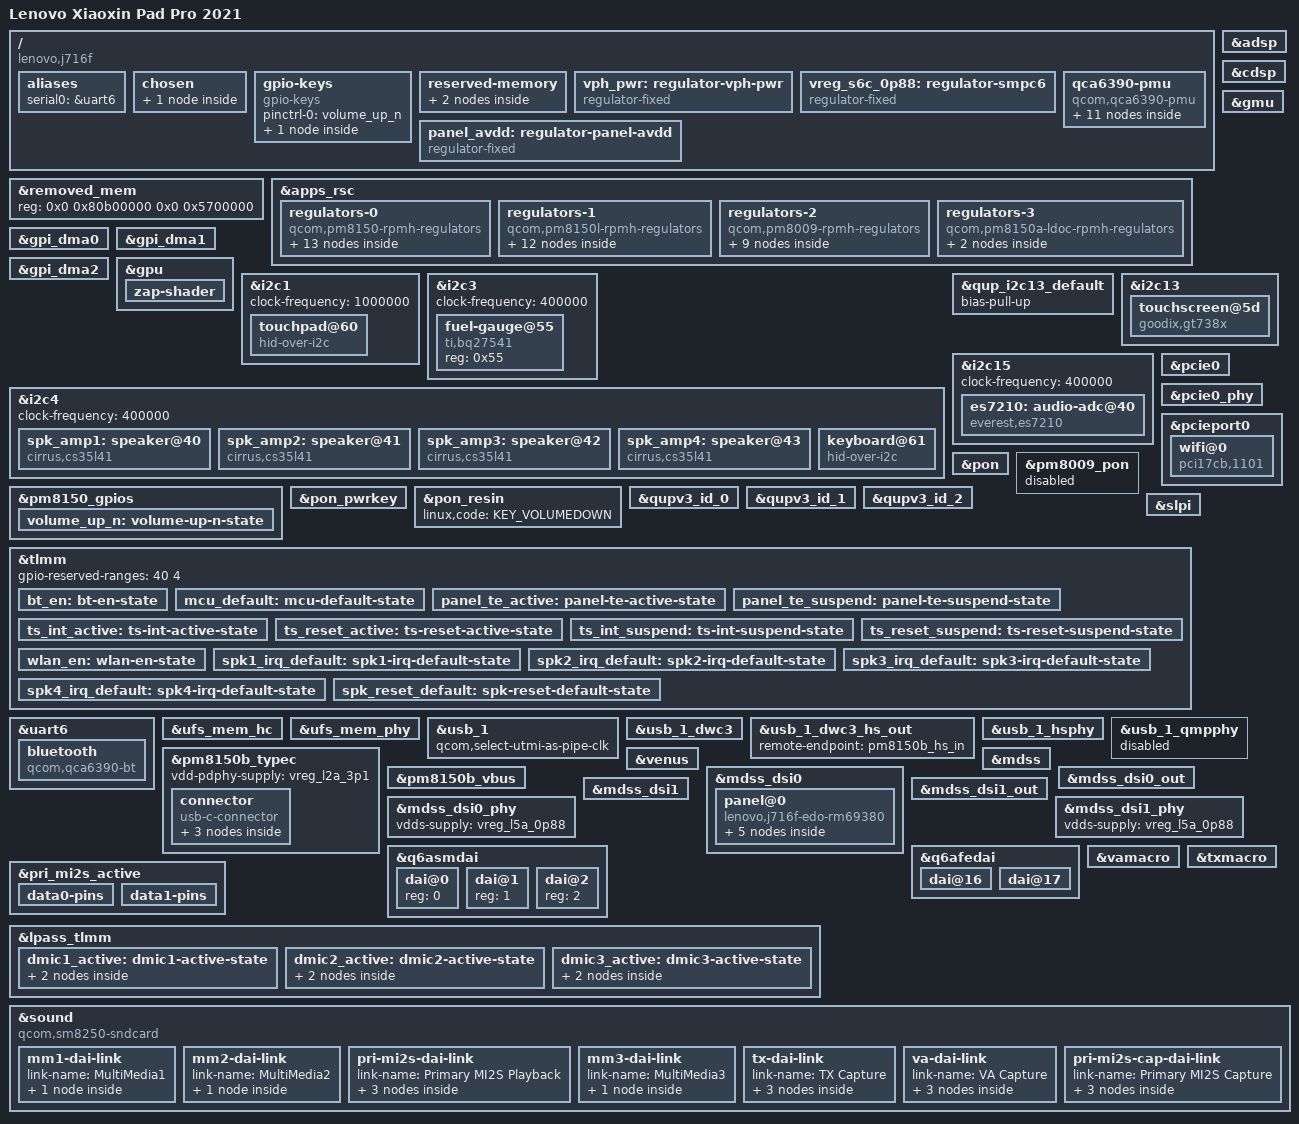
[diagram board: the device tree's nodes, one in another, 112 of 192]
// SPDX-License-Identifier: GPL-2.0-only
/*
 * Copyright (c) 2025, David Wronek <david@mainlining.org>
 */

/dts-v1/;

#include <dt-bindings/arm/qcom,ids.h>
#include <dt-bindings/gpio/gpio.h>
#include <dt-bindings/regulator/qcom,rpmh-regulator.h>
#include <dt-bindings/sound/qcom,q6afe.h>
#include <dt-bindings/usb/pd.h>
#include <dt-bindings/sound/qcom,q6asm.h>
#include "sm8250.dtsi"
#include "pm8009.dtsi"
#include "pm8150.dtsi"
#include "pm8150b.dtsi"
#include "pm8150l.dtsi"

/ {
	model = "Lenovo Xiaoxin Pad Pro 2021";
	compatible = "lenovo,j716f", "qcom,sm8250";
	chassis-type = "tablet";

	/* required for bootloader to select correct board */
	qcom,msm-id = <QCOM_ID_SM8250 0x20001>; /* SM8250 v2.1 */
	qcom,board-id = <0x2010008 0>;

	aliases {
		serial0 = &uart6;
	};

	chosen {
		#address-cells = <2>;
		#size-cells = <2>;
		ranges;

		framebuffer: framebuffer@9c000000 {
			compatible = "simple-framebuffer";
			reg = <0x0 0x9c000000 0x0 0x1f00000>;
			width = <2560>;
			height = <1600>;
			stride = <(2560 * 4)>;
			format = "a8r8g8b8";
		};
	};

	gpio-keys {
		compatible = "gpio-keys";

		pinctrl-names = "default";
		pinctrl-0 = <&volume_up_n>;

		key-vol-up {
			label = "Volume Up";
			linux,code = <KEY_VOLUMEUP>;
			gpios = <&pm8150_gpios 6 GPIO_ACTIVE_LOW>;
			debounce-interval = <15>;
			linux,can-disable;
			wakeup-source;
		};
	};

	reserved-memory {
		/*
		 * The bootloader loads the splash into the start of this
		 * region; the panel itself needs 2560x1600x4 = 16 MiB, so
		 * 31 MiB is plenty.  The size matters: everything after this
		 * reservation belongs to the general allocator, so it also
		 * bounds the simple-framebuffer below (see chosen).
		 */
		cont_splash_mem: memory@9c000000 {
			reg = <0x0 0x9c000000 0x0 0x1f00000>;
			no-map;
		};

		/*
		 * Phase M2: crash log that survives a reboot.  A watchdog or
		 * panic reset keeps the DDR contents for the next boot, which
		 * is exactly the case we need for the CPU-idle freeze seen on
		 * 2026-11-07 (no pstore at all back then).
		 *
		 * Phase M6: this used to sit at 0x9e100000, the last 2 MiB of
		 * the then 35 MiB simple-framebuffer range.  Both the fbdev
		 * console and pstore wrote the same pages, so every reset left
		 * /sys/fs/pstore empty (M3 and M5 both saw 0 entries).  Keep
		 * it strictly above both the splash reservation and the
		 * framebuffer: 0x9c000000 + 31 MiB = 0x9df00000, and the
		 * ramoops zone starts at 0x9f000000, well clear of it.
		 */
		ramoops@9f000000 {
			compatible = "ramoops";
			reg = <0x0 0x9f000000 0x0 0x200000>;
			record-size = <0x40000>;
			console-size = <0x80000>;
			pmsg-size = <0x40000>;
		};
	};

	vph_pwr: regulator-vph-pwr {
		compatible = "regulator-fixed";

		regulator-name = "vph_pwr";
		regulator-min-microvolt = <3700000>;
		regulator-max-microvolt = <3700000>;
		regulator-always-on;
		regulator-boot-on;
	};

	/* S6c is really ebi.lvl but it's there for supply map completeness sake. */
	vreg_s6c_0p88: regulator-smpc6 {
		compatible = "regulator-fixed";

		regulator-name = "vreg_s6c_0p88";
		regulator-min-microvolt = <880000>;
		regulator-max-microvolt = <880000>;
		regulator-always-on;

		vin-supply = <&vph_pwr>;
	};

	/*
	 * EDO EB50QBC73.A panel AVDD rail.  The 5.5 V value is the nominal
	 * rail generated by the board's boost; the GPIO is the real control.
	 */
	panel_avdd: regulator-panel-avdd {
		compatible = "regulator-fixed";

		regulator-name = "display_panel_avdd";
		regulator-min-microvolt = <5500000>;
		regulator-max-microvolt = <5500000>;
		regulator-enable-ramp-delay = <233>;
		regulator-boot-on;

		enable-gpios = <&tlmm 61 GPIO_ACTIVE_HIGH>;
		vin-supply = <&vph_pwr>;
	};

	qca6390-pmu {
		compatible = "qcom,qca6390-pmu";

		pinctrl-names = "default";
		pinctrl-0 = <&bt_en>, <&wlan_en>;

		vddaon-supply = <&vreg_s6a_0p6>;
		vddpmu-supply = <&vreg_s2f_0p5>;
		vddrfa0p95-supply = <&vreg_s6a_0p6>;
		vddrfa1p3-supply = <&vreg_s8c_1p2>;
		vddrfa1p9-supply = <&vreg_s5a_1p9>;
		vddpcie1p3-supply = <&vreg_s8c_1p2>;
		vddpcie1p9-supply = <&vreg_s5a_1p9>;
		vddio-supply = <&vreg_s4a_1p8>;

		wlan-enable-gpios = <&tlmm 20 GPIO_ACTIVE_HIGH>;
		bt-enable-gpios = <&tlmm 21 GPIO_ACTIVE_HIGH>;

		regulators {
			vreg_pmu_rfa_cmn: ldo0 {
				regulator-name = "vreg_pmu_rfa_cmn";
			};

			vreg_pmu_aon_0p59: ldo1 {
				regulator-name = "vreg_pmu_aon_0p59";
			};

			vreg_pmu_wlcx_0p8: ldo2 {
				regulator-name = "vreg_pmu_wlcx_0p8";
			};

			vreg_pmu_wlmx_0p85: ldo3 {
				regulator-name = "vreg_pmu_wlmx_0p85";
			};

			vreg_pmu_btcmx_0p85: ldo4 {
				regulator-name = "vreg_pmu_btcmx_0p85";
			};

			vreg_pmu_rfa_0p8: ldo5 {
				regulator-name = "vreg_pmu_rfa_0p8";
			};

			vreg_pmu_rfa_1p2: ldo6 {
				regulator-name = "vreg_pmu_rfa_1p2";
			};

			vreg_pmu_rfa_1p7: ldo7 {
				regulator-name = "vreg_pmu_rfa_1p7";
			};

			vreg_pmu_pcie_0p9: ldo8 {
				regulator-name = "vreg_pmu_pcie_0p9";
			};

			vreg_pmu_pcie_1p8: ldo9 {
				regulator-name = "vreg_pmu_pcie_1p8";
			};
		};
	};
};

/*
 * Candidate K1 of the v60 platform audit: the vendor tree keeps
 * 0x80b00000 + 0x5700000 (87 MiB) out of the allocator and ends that
 * range exactly where the TrustZone carveout ends -- 0x86200000, i.e.
 * qseecom@82400000 + 0x3e00000 ("TZApps Reserved" in the XBL EFI
 * memory map, "secapp-region" in the vendor DT).  The imported upstream
 * value stops 4 MiB short and leaves [0x85e00000, 0x86200000)
 * allocatable by Linux.  Restore the vendor extent; this is the only
 * variable the validation round changes.
 *
 * See docs/project/V60-PLATFORM-AUDIT.md, candidate K1.
 */
&removed_mem {
	reg = <0x0 0x80b00000 0x0 0x5700000>;
};

&adsp {
	firmware-name = "qcom/sm8250/LENOVO/J716F/adsp.mbn";
	status = "okay";
};

&apps_rsc {
	regulators-0 {
		compatible = "qcom,pm8150-rpmh-regulators";
		qcom,pmic-id = "a";

		vdd-s1-supply = <&vph_pwr>;
		vdd-s2-supply = <&vph_pwr>;
		vdd-s3-supply = <&vph_pwr>;
		vdd-s4-supply = <&vph_pwr>;
		vdd-s5-supply = <&vph_pwr>;
		vdd-s6-supply = <&vph_pwr>;
		vdd-s7-supply = <&vph_pwr>;
		vdd-s8-supply = <&vph_pwr>;
		vdd-s9-supply = <&vph_pwr>;
		vdd-s10-supply = <&vph_pwr>;
		vdd-l1-l8-l11-supply = <&vreg_s6c_0p88>;
		vdd-l2-l10-supply = <&vreg_bob>;
		vdd-l3-l4-l5-l18-supply = <&vreg_s6a_0p6>;
		vdd-l6-l9-supply = <&vreg_s8c_1p2>;
		vdd-l7-l12-l14-l15-supply = <&vreg_s5a_1p9>;
		vdd-l13-l16-l17-supply = <&vreg_bob>;

		/* (S1+S2+S3) - cx.lvl (ARC) */

		vreg_s4a_1p8: smps4 {
			regulator-name = "vreg_s4a_1p8";
			regulator-min-microvolt = <1800000>;
			regulator-max-microvolt = <1920000>;
			regulator-initial-mode = <RPMH_REGULATOR_MODE_HPM>;
			regulator-allow-set-load;
			regulator-allowed-modes = <RPMH_REGULATOR_MODE_LPM
						   RPMH_REGULATOR_MODE_HPM>;
		};

		vreg_s5a_1p9: smps5 {
			regulator-name = "vreg_s5a_1p9";
			regulator-min-microvolt = <1900000>;
			regulator-max-microvolt = <2040000>;
			regulator-initial-mode = <RPMH_REGULATOR_MODE_HPM>;
		};

		vreg_s6a_0p6: smps6 {
			regulator-name = "vreg_s6a_0p6";
			regulator-min-microvolt = <600000>;
			regulator-max-microvolt = <1128000>;
			regulator-initial-mode = <RPMH_REGULATOR_MODE_HPM>;
		};

		vreg_l2a_3p1: ldo2 {
			regulator-name = "vreg_l2a_3p1";
			regulator-min-microvolt = <3072000>;
			regulator-max-microvolt = <3072000>;
			regulator-initial-mode = <RPMH_REGULATOR_MODE_HPM>;
		};

		/* L3 is unused, L4 - lmx.lvl (ARC) */

		vreg_l5a_0p88: ldo5 {
			regulator-name = "vreg_l5a_0p88";
			regulator-min-microvolt = <880000>;
			regulator-max-microvolt = <880000>;
			regulator-initial-mode = <RPMH_REGULATOR_MODE_HPM>;
		};

		vreg_l6a_1p2: ldo6 {
			regulator-name = "vreg_l6a_1p2";
			regulator-min-microvolt = <1200000>;
			regulator-max-microvolt = <1200000>;
			regulator-initial-mode = <RPMH_REGULATOR_MODE_HPM>;
			regulator-allow-set-load;
			regulator-allowed-modes = <RPMH_REGULATOR_MODE_LPM
						   RPMH_REGULATOR_MODE_HPM>;
		};

		/* L7 is unused. */

		vreg_l9a_1p2: ldo9 {
			regulator-name = "vreg_l9a_1p2";
			regulator-min-microvolt = <1200000>;
			regulator-max-microvolt = <1200000>;
			regulator-initial-mode = <RPMH_REGULATOR_MODE_HPM>;
		};

		/* L10 is unused, L11 - lcx.lvl (ARC) */

		vreg_l12a_1p8: ldo12 {
			regulator-name = "vreg_l12a_1p8";
			regulator-min-microvolt = <1800000>;
			regulator-max-microvolt = <1800000>;
			regulator-initial-mode = <RPMH_REGULATOR_MODE_HPM>;
		};

		vreg_l13a_3p0: ldo13 {
			regulator-name = "vreg_l13a_3p0";
			regulator-min-microvolt = <3008000>;
			regulator-max-microvolt = <3008000>;
			regulator-initial-mode = <RPMH_REGULATOR_MODE_HPM>;
		};

		vreg_l14a_1p88: ldo14 {
			regulator-name = "vreg_l14a_1p88";
			regulator-min-microvolt = <1800000>;
			regulator-max-microvolt = <1880000>;
			regulator-initial-mode = <RPMH_REGULATOR_MODE_HPM>;
		};

		/* L15 is unused. */

		vreg_l16a_3p3: ldo16 {
			regulator-name = "vreg_l16a_3p3";
			regulator-min-microvolt = <3024000>;
			regulator-max-microvolt = <3304000>;
			regulator-initial-mode = <RPMH_REGULATOR_MODE_HPM>;
		};

		vreg_l17a_2p5: ldo17 {
			regulator-name = "vreg_l17a_2p5";
			regulator-min-microvolt = <2496000>;
			regulator-max-microvolt = <3008000>;
			regulator-initial-mode = <RPMH_REGULATOR_MODE_HPM>;
			regulator-allow-set-load;
			regulator-allowed-modes = <RPMH_REGULATOR_MODE_LPM
						   RPMH_REGULATOR_MODE_HPM>;
		};

		vreg_l18a_0p9: ldo18 {
			regulator-name = "vreg_l18a_0p9";
			regulator-min-microvolt = <800000>;
			regulator-max-microvolt = <920000>;
			regulator-initial-mode = <RPMH_REGULATOR_MODE_HPM>;
		};
	};

	/*
	 * Remaining regulators that are not yet supported:
	 * OLEDB: 4925000-8100000
	 * ab: 4600000-6100000
	 * ibb: 800000-5400000
	 */

	regulators-1 {
		compatible = "qcom,pm8150l-rpmh-regulators";
		qcom,pmic-id = "c";

		vdd-s1-supply = <&vph_pwr>;
		vdd-s2-supply = <&vph_pwr>;
		vdd-s3-supply = <&vph_pwr>;
		vdd-s4-supply = <&vph_pwr>;
		vdd-s5-supply = <&vph_pwr>;
		vdd-s6-supply = <&vph_pwr>;
		vdd-s7-supply = <&vph_pwr>;
		vdd-s8-supply = <&vph_pwr>;
		vdd-l1-l8-supply = <&vreg_s4a_1p8>;
		vdd-l2-l3-supply = <&vreg_s8c_1p2>;
		vdd-l4-l5-l6-supply = <&vreg_bob>;
		vdd-l7-l11-supply = <&vreg_bob>;
		vdd-l9-l10-supply = <&vreg_bob>;
		vdd-bob-supply = <&vph_pwr>;

		vreg_bob: bob {
			regulator-name = "vreg_bob";
			regulator-min-microvolt = <3008000>;
			regulator-max-microvolt = <3960000>;
			regulator-initial-mode = <RPMH_REGULATOR_MODE_AUTO>;
		};

		/*
		 * S1-S6 are ARCs:
		 * (S1+S2) - gfx.lvl,
		 * S3 - mx.lvl,
		 * (S4+S5) - mmcx.lvl,
		 * S6 - ebi.lvl
		 */

		vreg_s7c_0p35: smps7 {
			regulator-name = "vreg_s7c_0p35";
			regulator-min-microvolt = <348000>;
			regulator-max-microvolt = <1000000>;
			regulator-initial-mode = <RPMH_REGULATOR_MODE_HPM>;
		};

		vreg_s8c_1p2: smps8 {
			regulator-name = "vreg_s8c_1p2";
			regulator-min-microvolt = <1200000>;
			regulator-max-microvolt = <1400000>;
			regulator-initial-mode = <RPMH_REGULATOR_MODE_HPM>;
		};

		vreg_l1c_1p8: ldo1 {
			regulator-name = "vreg_l1c_1p8";
			regulator-min-microvolt = <1800000>;
			regulator-max-microvolt = <1800000>;
			regulator-initial-mode = <RPMH_REGULATOR_MODE_HPM>;
		};

		/* L2 is unused. */

		vreg_l3c_0p8: ldo3 {
			regulator-name = "vreg_l3c_0p8";
			regulator-min-microvolt = <800000>;
			regulator-max-microvolt = <1200000>;
			regulator-initial-mode = <RPMH_REGULATOR_MODE_HPM>;
		};

		/* L4 is unused. */

		vreg_l5c_1p8: ldo5 {
			regulator-name = "vreg_l5c_1p8";
			regulator-min-microvolt = <1800000>;
			regulator-max-microvolt = <2800000>;
			regulator-initial-mode = <RPMH_REGULATOR_MODE_HPM>;
		};

		vreg_l6c_2p9: ldo6 {
			regulator-name = "vreg_l6c_2p9";
			regulator-min-microvolt = <1800000>;
			regulator-max-microvolt = <2960000>;
			regulator-initial-mode = <RPMH_REGULATOR_MODE_HPM>;
			regulator-allow-set-load;
			regulator-allowed-modes = <RPMH_REGULATOR_MODE_LPM
						   RPMH_REGULATOR_MODE_HPM>;
		};

		vreg_l7c_2p85: ldo7 {
			regulator-name = "vreg_l7c_2p85";
			regulator-min-microvolt = <2856000>;
			regulator-max-microvolt = <3104000>;
			regulator-initial-mode = <RPMH_REGULATOR_MODE_HPM>;
		};

		vreg_l8c_1p8: ldo8 {
			regulator-name = "vreg_l8c_1p8";
			regulator-min-microvolt = <1800000>;
			regulator-max-microvolt = <1800000>;
			regulator-initial-mode = <RPMH_REGULATOR_MODE_HPM>;
		};

		vreg_l9c_2p9: ldo9 {
			regulator-name = "vreg_l9c_2p9";
			regulator-min-microvolt = <2704000>;
			regulator-max-microvolt = <2960000>;
			regulator-initial-mode = <RPMH_REGULATOR_MODE_HPM>;
			regulator-allow-set-load;
			regulator-allowed-modes = <RPMH_REGULATOR_MODE_LPM
						   RPMH_REGULATOR_MODE_HPM>;
		};

		vreg_l10c_3p3: ldo10 {
			regulator-name = "vreg_l10c_3p3";
			regulator-min-microvolt = <3000000>;
			regulator-max-microvolt = <3312000>;
			regulator-initial-mode = <RPMH_REGULATOR_MODE_HPM>;
		};

		vreg_l11c_3p3: ldo11 {
			regulator-name = "vreg_l11c_3p0";
			regulator-min-microvolt = <3104000>;
			regulator-max-microvolt = <3304000>;
			regulator-initial-mode = <RPMH_REGULATOR_MODE_HPM>;
		};
	};

	regulators-2 {
		compatible = "qcom,pm8009-rpmh-regulators";
		qcom,pmic-id = "f";

		vdd-s1-supply = <&vph_pwr>;
		vdd-s2-supply = <&vreg_bob>;
		vdd-l2-supply = <&vreg_s8c_1p2>;
		vdd-l5-l6-supply = <&vreg_bob>;
		vdd-l7-supply = <&vreg_s4a_1p8>;

		vreg_s1f_1p2: smps1 {
			regulator-name = "vreg_s1f_1p2";
			regulator-min-microvolt = <1200000>;
			regulator-max-microvolt = <1200000>;
			regulator-initial-mode = <RPMH_REGULATOR_MODE_HPM>;
		};

		vreg_s2f_0p5: smps2 {
			regulator-name = "vreg_s2f_0p5";
			regulator-min-microvolt = <512000>;
			regulator-max-microvolt = <1100000>;
			regulator-initial-mode = <RPMH_REGULATOR_MODE_HPM>;
		};

		vreg_l1f_1p2: ldo1 {
			regulator-name = "vreg_l1f_1p2";
			regulator-min-microvolt = <1104000>;
			regulator-max-microvolt = <1200000>;
			regulator-initial-mode = <RPMH_REGULATOR_MODE_HPM>;
		};

		vreg_l2f_1p2: ldo2 {
			regulator-name = "vreg_l2f_1p1";
			regulator-min-microvolt = <1200000>;
			regulator-max-microvolt = <1200000>;
			regulator-initial-mode = <RPMH_REGULATOR_MODE_HPM>;
		};

		vreg_l3f_1p2: ldo3 {
			regulator-name = "vreg_l3f_1p2";
			regulator-min-microvolt = <1056000>;
			regulator-max-microvolt = <1200000>;
			regulator-initial-mode = <RPMH_REGULATOR_MODE_HPM>;
		};

		vreg_l4f_1p3: ldo4 {
			regulator-name = "vreg_l4f_1p3";
			regulator-min-microvolt = <1096000>;
			regulator-max-microvolt = <1304000>;
			regulator-initial-mode = <RPMH_REGULATOR_MODE_HPM>;
		};

		vreg_l5f_2p8: ldo5 {
			regulator-name = "vreg_l5f_2p85";
			regulator-min-microvolt = <2800000>;
			regulator-max-microvolt = <3000000>;
			regulator-initial-mode = <RPMH_REGULATOR_MODE_HPM>;
		};

		vreg_l6f_2p8: ldo6 {
			regulator-name = "vreg_l6f_2p8";
			regulator-min-microvolt = <2800000>;
			regulator-max-microvolt = <3000000>;
			regulator-initial-mode = <RPMH_REGULATOR_MODE_HPM>;
		};

		vreg_l7f_1p8: ldo7 {
			regulator-name = "vreg_l7f_1p8";
			regulator-min-microvolt = <1800000>;
			regulator-max-microvolt = <1800000>;
			regulator-initial-mode = <RPMH_REGULATOR_MODE_HPM>;
		};
	};

	/*
	 * PM8150A LDOs.  The touch controller's 1.8 V core rail is ldoc1
	 * (vendor: pm8150a_l1 -> goodix-gt738x@5d vdd-supply); ldoc10 is
	 * used by the fingerprint sensor.
	 */
	regulators-3 {
		compatible = "qcom,pm8150a-ldoc-rpmh-regulators";
		qcom,pmic-id = "d";

		vdd-l1-l2-supply = <&vph_pwr>;
		vdd-l3-supply = <&vph_pwr>;
		vdd-l4-l5-l6-supply = <&vph_pwr>;
		vdd-l7-supply = <&vph_pwr>;
		vdd-l8-supply = <&vph_pwr>;
		vdd-l9-l10-supply = <&vph_pwr>;
		vdd-l11-supply = <&vph_pwr>;
		vdd-l12-supply = <&vph_pwr>;

		vreg_l1d_1p8: ldoc1 {
			regulator-name = "vreg_l1d_1p8";
			regulator-min-microvolt = <1800000>;
			regulator-max-microvolt = <1800000>;
		};

		vreg_l10d_3p0: ldoc10 {
			regulator-name = "vreg_l10d_3p0";
			regulator-min-microvolt = <3000000>;
			regulator-max-microvolt = <3312000>;
			regulator-initial-mode = <RPMH_REGULATOR_MODE_HPM>;
		};
	};
};

&cdsp {
	firmware-name = "qcom/sm8250/LENOVO/J716F/cdsp.mbn";
	status = "okay";
};

&gmu {
	status = "okay";
};

&gpi_dma0 {
	status = "okay";
};

&gpi_dma1 {
	status = "okay";
};

&gpi_dma2 {
	status = "okay";
};

&gpu {
	status = "okay";

	zap-shader {
		memory-region = <&gpu_mem>;
		firmware-name = "qcom/sm8250/LENOVO/J716F/a650_zap.mbn";
	};
};

&i2c1 {
	clock-frequency = <1000000>;
	status = "okay";

	touchpad@60 {
		compatible = "hid-over-i2c";
		reg = <0x60>;

		vdd-supply = <&vreg_l16a_3p3>;
		vddl-supply = <&vreg_l8c_1p8>;

		interrupt-parent = <&tlmm>;
		interrupts = <14 IRQ_TYPE_LEVEL_LOW>;

		hid-descr-addr = <0x01>;
		post-power-on-delay-ms = <100>;
	};
};

&i2c3 {
	clock-frequency = <400000>;
	status = "okay";

	fuel-gauge@55 {
		compatible = "ti,bq27541";
		reg = <0x55>;
	};
};

&i2c4 {
	clock-frequency = <400000>;
	status = "okay";

	/* onsemi NB7VPQ904M USB redriver @ 19 */

	/*
	 * Four CS35L41 speaker amplifiers.  All share reset gpio 131 and
	 * the primary MI2S bit clock; IRQs are 67, 113, 126 and 68.
	 * VA is the 3.3 V logic rail, VP is the battery rail feeding the
	 * internal boost converter.
	 */
	spk_amp1: speaker@40 {
		compatible = "cirrus,cs35l41";
		reg = <0x40>;
		#sound-dai-cells = <1>;

		interrupt-parent = <&tlmm>;
		interrupts = <67 IRQ_TYPE_LEVEL_LOW>;
		interrupt-controller;
		#interrupt-cells = <2>;
		interrupt-names = "cs35l41_1_irq";

		pinctrl-names = "default";
		pinctrl-0 = <&spk1_irq_default &spk_reset_default>;

		reset-gpios = <&tlmm 131 GPIO_ACTIVE_HIGH>;

		VA-supply = <&vreg_l16a_3p3>;
		VP-supply = <&vph_pwr>;

		cirrus,boost-type = <0>;
		cirrus,boost-peak-milliamp = <3500>;
		cirrus,boost-ind-nanohenry = <1000>;
		cirrus,boost-cap-microfarad = <15>;
		/* Without a boost target the amplifier stays silent. */
		cirrus,boost-ctl-millivolt = <4600>;
		cirrus,asp-sdout-hiz = <3>;
		cirrus,gpio2-src-select = <4>;
		cirrus,gpio2-output-enable;
	};

	spk_amp2: speaker@41 {
		compatible = "cirrus,cs35l41";
		reg = <0x41>;
		#sound-dai-cells = <1>;
		sound-name-prefix = "SPK2";

		interrupt-parent = <&tlmm>;
		interrupts = <113 IRQ_TYPE_LEVEL_LOW>;
		interrupt-controller;
		#interrupt-cells = <2>;
		interrupt-names = "cs35l41_2_irq";

		pinctrl-names = "default";
		pinctrl-0 = <&spk2_irq_default>;

		reset-gpios = <&tlmm 131 GPIO_ACTIVE_HIGH>;

		VA-supply = <&vreg_l16a_3p3>;
		VP-supply = <&vph_pwr>;

		cirrus,boost-type = <0>;
		cirrus,boost-peak-milliamp = <3500>;
		cirrus,boost-ind-nanohenry = <1000>;
		cirrus,boost-cap-microfarad = <15>;
		cirrus,boost-ctl-millivolt = <4600>;
		cirrus,asp-sdout-hiz = <3>;
		cirrus,gpio2-src-select = <4>;
		cirrus,gpio2-output-enable;
	};

	spk_amp3: speaker@42 {
		compatible = "cirrus,cs35l41";
		reg = <0x42>;
		#sound-dai-cells = <1>;
		sound-name-prefix = "SPK3";

		interrupt-parent = <&tlmm>;
		interrupts = <126 IRQ_TYPE_LEVEL_LOW>;
		interrupt-controller;
		#interrupt-cells = <2>;
		interrupt-names = "cs35l41_3_irq";

		pinctrl-names = "default";
		pinctrl-0 = <&spk3_irq_default>;

		reset-gpios = <&tlmm 131 GPIO_ACTIVE_HIGH>;

		VA-supply = <&vreg_l16a_3p3>;
		VP-supply = <&vph_pwr>;

		cirrus,boost-type = <0>;
		cirrus,boost-peak-milliamp = <3500>;
		cirrus,boost-ind-nanohenry = <1000>;
		cirrus,boost-cap-microfarad = <15>;
		cirrus,boost-ctl-millivolt = <4600>;
		cirrus,asp-sdout-hiz = <3>;
		cirrus,gpio2-src-select = <4>;
		cirrus,gpio2-output-enable;
	};

	spk_amp4: speaker@43 {
		compatible = "cirrus,cs35l41";
		reg = <0x43>;
		#sound-dai-cells = <1>;
		sound-name-prefix = "SPK4";

		interrupt-parent = <&tlmm>;
		interrupts = <68 IRQ_TYPE_LEVEL_LOW>;
		interrupt-controller;
		#interrupt-cells = <2>;
		interrupt-names = "cs35l41_4_irq";

		pinctrl-names = "default";
		pinctrl-0 = <&spk4_irq_default>;

		reset-gpios = <&tlmm 131 GPIO_ACTIVE_HIGH>;

		VA-supply = <&vreg_l16a_3p3>;
		VP-supply = <&vph_pwr>;

		cirrus,boost-type = <0>;
		cirrus,boost-peak-milliamp = <3500>;
		cirrus,boost-ind-nanohenry = <1000>;
		cirrus,boost-cap-microfarad = <15>;
		cirrus,boost-ctl-millivolt = <4600>;
		cirrus,asp-sdout-hiz = <3>;
		cirrus,gpio2-src-select = <4>;
		cirrus,gpio2-output-enable;
	};

	keyboard@61 {
		compatible = "hid-over-i2c";
		reg = <0x61>;

		vdd-supply = <&vreg_l16a_3p3>;
		vddl-supply = <&vreg_l8c_1p8>;

		pinctrl-names = "default";
		pinctrl-0 = <&mcu_default>;

		interrupt-parent = <&tlmm>;
		interrupts = <11 IRQ_TYPE_LEVEL_LOW>;

		hid-descr-addr = <0x1>;
		post-power-on-delay-ms = <100>;
	};
};

/*
 * The GT7385P touch controller is a GT9xx-protocol part (16-bit register
 * addresses), not a Berlin part.  The vendor uses 100 kHz on this long,
 * thin FPC and the GENI controller takes the GPI-DMA path otherwise; force
 * the FIFO/PIO path for this bus.
 */
&qup_i2c13_default {
	bias-pull-up;
};

&i2c13 {
	clock-frequency = <100000>;
	status = "okay";
	qcom,force-fifo;

	touchscreen@5d {
		compatible = "goodix,gt738x";
		reg = <0x5d>;
		goodix,debug-reports;

		interrupt-parent = <&tlmm>;
		interrupts = <39 IRQ_TYPE_EDGE_FALLING>;

		/*
		 * Both GPIOs are ACTIVE_HIGH: goodix_reset_no_int_sync()
		 * drives INT as an output to select the 0x5d I2C address
		 * before releasing reset.  An ACTIVE_LOW irq-gpios would
		 * select 0x14 instead and every read at 0x5d would time out.
		 */
		irq-gpios = <&tlmm 39 GPIO_ACTIVE_HIGH>;
		reset-gpios = <&tlmm 38 GPIO_ACTIVE_HIGH>;

		/*
		 * goodix.c prefixes this with "goodix/", so the blob is at
		 * /lib/firmware/goodix/j716f_cfg.bin.  Without the panel
		 * configuration the controller never enters normal reporting
		 * mode.
		 */
		goodix,config-name = "j716f_cfg.bin";

		/*
		 * Vendor rail map:
		 *   pm8150a_l1  (1.8 V) -> vdd-supply / avdd-supply
		 *   pm8150_l13  (3.0 V) -> AVDD28-supply
		 *   pm8150_l14  (1.8 V) -> VDDIO-supply / vddio-supply
		 */
		avdd-supply = <&vreg_l1d_1p8>;
		vdd-supply = <&vreg_l1d_1p8>;
		vddio-supply = <&vreg_l14a_1p88>;
		AVDD28-supply = <&vreg_l13a_3p0>;
		VDDIO-supply = <&vreg_l14a_1p88>;

		pinctrl-names = "default", "sleep";
		pinctrl-0 = <&ts_int_active &ts_reset_active>;
		pinctrl-1 = <&ts_int_suspend &ts_reset_suspend>;

		/* Coordinates already match display orientation. */
		touchscreen-size-x = <2560>;
		touchscreen-size-y = <1600>;
	};
};

&i2c15 {
	clock-frequency = <400000>;
	status = "okay";

	/* SMB1390 charger @ 10 */
	/* FSA4480 USB audio switch @ 43 */
	/* RTC6226 FM receiver @ 64 */
	/* HL6111R wireless charging IC @ 25 */

	/*
	 * Four-microphone ADC.  Its serial output feeds the primary MI2S
	 * capture direction, so data0/data1 must stay inputs on the SoC.
	 */
	es7210: audio-adc@40 {
		compatible = "everest,es7210";
		reg = <0x40>;

		vd-supply = <&vreg_l16a_3p3>;
		vp-supply = <&vreg_l8c_1p8>;

		#sound-dai-cells = <0>;
	};
};

&pcie0 {
	status = "okay";
};

&pcie0_phy {
	vdda-phy-supply = <&vreg_l5a_0p88>;
	vdda-pll-supply = <&vreg_l9a_1p2>;
	status = "okay";
};

&pcieport0 {
	wifi@0 {
		compatible = "pci17cb,1101";
		reg = <0x10000 0x0 0x0 0x0 0x0>;

		vddrfacmn-supply = <&vreg_pmu_rfa_cmn>;
		vddaon-supply = <&vreg_pmu_aon_0p59>;
		vddwlcx-supply = <&vreg_pmu_wlcx_0p8>;
		vddwlmx-supply = <&vreg_pmu_wlmx_0p85>;
		vddrfa0p8-supply = <&vreg_pmu_rfa_0p8>;
		vddrfa1p2-supply = <&vreg_pmu_rfa_1p2>;
		vddrfa1p7-supply = <&vreg_pmu_rfa_1p7>;
		vddpcie0p9-supply = <&vreg_pmu_pcie_0p9>;
		vddpcie1p8-supply = <&vreg_pmu_pcie_1p8>;
	};
};

&pm8150_gpios {
	volume_up_n: volume-up-n-state {
		pins = "gpio6";
		function = "normal";
		bias-pull-up;
		input-enable;
		power-source = <1>;
	};
};

&pon {
	/*
	 * Phase L4: PM8150 PON 的 soft reboot reason，ABL 用它决定冷启动目标。
	 * 数值沿用 Sony/Xiaomi SM8250 主线 DTS 的 GEN2 约定。
	 */
	mode-bootloader = <0x2>;
	mode-recovery = <0x1>;
};

/*
 * Phase L4: reboot-mode class 用 driver name（"qcom-pon"）给设备命名，
 * 同一时刻只能注册一个。pm8009 的 PON 没有 pwrkey，却会先占用这个名字，
 * 导致 PM8150 PON probe 失败（-EEXIST），连带 pwrkey/resin 都不注册。
 * 把它禁用，让 PM8150 PON 注册并写入正确的 reboot reason。
 */
&pm8009_pon {
	status = "disabled";
};

&pon_pwrkey {
	status = "okay";
};

&pon_resin {
	linux,code = <KEY_VOLUMEDOWN>;
	status = "okay";
};

&qupv3_id_0 {
	status = "okay";
};

&qupv3_id_1 {
	status = "okay";
};

&qupv3_id_2 {
	status = "okay";
};

&slpi {
	firmware-name = "qcom/sm8250/LENOVO/J716F/slpi.mbn";
	status = "okay";
};

&tlmm {
	gpio-reserved-ranges = <40 4>;

	bt_en: bt-en-state {
		pins = "gpio21";
		function = "gpio";
		drive-strength = <16>;
		output-low;
		bias-pull-up;
	};

	mcu_default: mcu-default-state {
		pins = "gpio11", "gpio14", "gpio25";
		function = "gpio";
		bias-disable;
	};

	panel_te_active: panel-te-active-state {
		pins = "gpio66";
		function = "mdp_vsync";
		drive-strength = <2>;
		bias-pull-down;
	};

	panel_te_suspend: panel-te-suspend-state {
		pins = "gpio66";
		function = "mdp_vsync";
		drive-strength = <2>;
		bias-pull-down;
	};

	ts_int_active: ts-int-active-state {
		pins = "gpio39";
		function = "gpio";
		drive-strength = <8>;
		bias-pull-up;
	};

	ts_reset_active: ts-reset-active-state {
		pins = "gpio38";
		function = "gpio";
		drive-strength = <8>;
		bias-pull-up;
	};

	ts_int_suspend: ts-int-suspend-state {
		pins = "gpio39";
		function = "gpio";
		drive-strength = <2>;
		bias-pull-down;
	};

	ts_reset_suspend: ts-reset-suspend-state {
		pins = "gpio38";
		function = "gpio";
		drive-strength = <2>;
		bias-pull-down;
	};

	wlan_en: wlan-en-state {
		pins = "gpio20";
		function = "gpio";
		drive-strength = <16>;
		output-low;
		bias-pull-up;
	};

	spk1_irq_default: spk1-irq-default-state {
		pins = "gpio67";
		function = "gpio";
		drive-strength = <2>;
		bias-pull-up;
	};

	spk2_irq_default: spk2-irq-default-state {
		pins = "gpio113";
		function = "gpio";
		drive-strength = <2>;
		bias-pull-up;
	};

	spk3_irq_default: spk3-irq-default-state {
		pins = "gpio126";
		function = "gpio";
		drive-strength = <2>;
		bias-pull-up;
	};

	spk4_irq_default: spk4-irq-default-state {
		pins = "gpio68";
		function = "gpio";
		drive-strength = <2>;
		bias-pull-up;
	};

	spk_reset_default: spk-reset-default-state {
		pins = "gpio131";
		function = "gpio";
		drive-strength = <16>;
		bias-pull-up;
		output-high;
	};
};

&uart6 {
	status = "okay";

	bluetooth {
		compatible = "qcom,qca6390-bt";

		vddrfacmn-supply = <&vreg_pmu_rfa_cmn>;
		vddaon-supply = <&vreg_pmu_aon_0p59>;
		vddbtcmx-supply = <&vreg_pmu_btcmx_0p85>;
		vddrfa0p8-supply = <&vreg_pmu_rfa_0p8>;
		vddrfa1p2-supply = <&vreg_pmu_rfa_1p2>;
		vddrfa1p7-supply = <&vreg_pmu_rfa_1p7>;

		/*
		 * v42 真机：pm_test 的 UART suspend/resume 会让 QCA6390
		 * 重新初始化失败（0xfc00/0x0c03 -110），挂起后蓝牙变 DOWN。
		 * 保留 BT 供电、跳过 in-band sleep，等 v43 验证。
		 */
		qcom,no-ibs-sleep;

		/*
		 * Phase L4: 属性按 LSB-first 编码。内核把它解释为
		 * 02:00:00:00:5A:AD（本地管理、单播），不是数组顺序。
		 */
		local-bd-address = [ad 5a 00 00 00 02];
	};
};

&ufs_mem_hc {
	vcc-supply = <&vreg_l17a_2p5>;
	vcc-max-microamp = <800000>;
	vccq-supply = <&vreg_l6a_1p2>;
	vccq-max-microamp = <800000>;
	vccq2-supply = <&vreg_s4a_1p8>;
	vccq2-max-microamp = <800000>;

	status = "okay";
};

&ufs_mem_phy {
	vdda-phy-supply = <&vreg_l5a_0p88>;
	vdda-pll-supply = <&vreg_l9a_1p2>;

	status = "okay";
};

&usb_1 {
	/*
	 * The board wires the USB-C connector to the PM8150B Type-C block
	 * and only brings out USB 2.0.  Select the UTMI pipe clock so DWC3
	 * does not depend on the QMP combo PHY.
	 */
	qcom,select-utmi-as-pipe-clk;
	status = "okay";
};

&usb_1_dwc3 {
	dr_mode = "otg";
	maximum-speed = "high-speed";
	phys = <&usb_1_hsphy>;
	phy-names = "usb2-phy";
	usb-role-switch;
};

&usb_1_dwc3_hs_out {
	remote-endpoint = <&pm8150b_hs_in>;
};

&usb_1_hsphy {
	vdda-pll-supply = <&vreg_l5a_0p88>;
	vdda18-supply = <&vreg_l12a_1p8>;
	vdda33-supply = <&vreg_l2a_3p1>;

	status = "okay";
};

&usb_1_qmpphy {
	/delete-property/ orientation-switch;

	vdda-phy-supply = <&vreg_l9a_1p2>;
	vdda-pll-supply = <&vreg_l18a_0p9>;

	/* USB 2.0 only; the Type-C role switch lives in the PMIC. */
	status = "disabled";
};

&pm8150b_typec {
	vdd-pdphy-supply = <&vreg_l2a_3p1>;
	status = "okay";

	connector {
		compatible = "usb-c-connector";

		op-sink-microwatt = <10000000>;
		power-role = "dual";
		data-role = "dual";
		self-powered;

		vbus-supply = <&pm8150b_vbus>;

		source-pdos = <PDO_FIXED(5000, 1500,
					 PDO_FIXED_DUAL_ROLE |
					 PDO_FIXED_USB_COMM |
					 PDO_FIXED_DATA_SWAP)>;

		sink-pdos = <PDO_FIXED(5000, 3000,
				       PDO_FIXED_DUAL_ROLE |
				       PDO_FIXED_USB_COMM |
				       PDO_FIXED_DATA_SWAP)
				       PDO_VAR(5000, 12000, 5000)>;

		ports {
			#address-cells = <1>;
			#size-cells = <0>;

			port@0 {
				reg = <0>;

				pm8150b_hs_in: endpoint {
					remote-endpoint = <&usb_1_dwc3_hs_out>;
				};
			};
		};
	};
};

&pm8150b_vbus {
	regulator-min-microamp = <500000>;
	regulator-max-microamp = <3000000>;
	status = "okay";
};

&venus {
	firmware-name = "qcom/sm8250/LENOVO/J716F/venus.mbn";
	status = "okay";
};

/*
 * Display: EDO EB50QBC73.A AMOLED (Raydium RM69380), dual-DSI cmd mode.
 *
 * The board keeps the panel powered by the bootloader and exposes a
 * simple-framebuffer; enabling mdss/DSI gives MDSS_GDSC a real consumer so
 * the genpd sync_state path cannot power it off behind the driver's back.
 */
&mdss {
	status = "okay";
};

&mdss_dsi0 {
	status = "okay";

	vdda-supply = <&vreg_l9a_1p2>;

	qcom,dual-dsi-mode;
	qcom,sync-dual-dsi;
	qcom,master-dsi;

	pinctrl-names = "default", "sleep";
	pinctrl-0 = <&panel_te_active>;
	pinctrl-1 = <&panel_te_suspend>;

	panel@0 {
		compatible = "lenovo,j716f-edo-rm69380", "raydium,rm69380";
		reg = <0>;

		vddio-supply = <&vreg_l14a_1p88>;
		avdd-supply = <&panel_avdd>;
		reset-gpios = <&tlmm 75 GPIO_ACTIVE_LOW>;

		ports {
			#address-cells = <1>;
			#size-cells = <0>;

			port@0 {
				reg = <0>;

				panel_in_0: endpoint {
					remote-endpoint = <&mdss_dsi0_out>;
				};
			};

			port@1 {
				reg = <1>;

				panel_in_1: endpoint {
					remote-endpoint = <&mdss_dsi1_out>;
				};
			};
		};
	};
};

&mdss_dsi0_out {
	data-lanes = <0 1 2 3>;
	remote-endpoint = <&panel_in_0>;
};

&mdss_dsi0_phy {
	status = "okay";

	vdds-supply = <&vreg_l5a_0p88>;
};

&mdss_dsi1 {
	status = "okay";

	vdda-supply = <&vreg_l9a_1p2>;

	qcom,dual-dsi-mode;
	qcom,sync-dual-dsi;
};

&mdss_dsi1_out {
	data-lanes = <0 1 2 3>;
	remote-endpoint = <&panel_in_1>;
};

&mdss_dsi1_phy {
	status = "okay";

	vdds-supply = <&vreg_l5a_0p88>;
};

/*
 * Phase L4: 不开 allow-set-time。
 *
 * v22 证明 AP 对 PM8150 RTC 的写通道被 SPMI arbiter 的 APID owner 拒绝，
 * 返回 EPERM（安全失败）；v23 绕过该检查后，写请求真正下发，PMIC 总线
 * 没有正常应答，整机在 hwclock -w 时挂死。RTC 只读，系统时间由
 * fake-hwclock + NTP 兜底，因此这里明确不声明 RTC 可写。
 */

/*
 * Phase L5 audio: four CS35L41 amplifiers on primary MI2S RX, ES7210 on
 * primary MI2S TX, DMIC capture through the VA/TX macros, and the Q6ASM
 * front ends.  The topology follows the working 6.15.11 J716F reference.
 */
&q6asmdai {
	dai@0 {
		reg = <0>;
	};

	dai@1 {
		reg = <1>;
	};

	dai@2 {
		reg = <2>;
	};
};

&q6afedai {
	/*
	 * Speakers use SD1, the ES7210 microphone ADC uses SD0.
	 * mainline builds the line mask with BIT(index).
	 */
	dai@16 {
		reg = <PRIMARY_MI2S_RX>;
		qcom,sd-lines = <1>;
	};

	dai@17 {
		reg = <PRIMARY_MI2S_TX>;
		qcom,sd-lines = <0>;
	};
};

/*
 * The primary MI2S data lines are driven by the ES7210 in the capture
 * direction.  sm8250.dtsi marks data0/data1 output-high, which makes the
 * SoC fight the codec and turns every recording into silence; delete the
 * property so the pads stay inputs.
 */
&pri_mi2s_active {
	data0-pins {
		/delete-property/ output-high;
	};

	data1-pins {
		/delete-property/ output-high;
	};
};

/* DMIC pad groups on the LPASS LPI pin controller. */
&lpass_tlmm {
	dmic1_active: dmic1-active-state {
		clk-pins {
			pins = "gpio6";
			function = "dmic1_clk";
			drive-strength = <8>;
			output-high;
		};

		data-pins {
			pins = "gpio7";
			function = "dmic1_data";
			drive-strength = <8>;
			input-enable;
		};
	};

	dmic2_active: dmic2-active-state {
		clk-pins {
			pins = "gpio8";
			function = "dmic2_clk";
			drive-strength = <8>;
			output-high;
		};

		data-pins {
			pins = "gpio9";
			function = "dmic2_data";
			drive-strength = <8>;
			input-enable;
		};
	};

	dmic3_active: dmic3-active-state {
		clk-pins {
			pins = "gpio12";
			function = "dmic3_clk";
			drive-strength = <8>;
			output-high;
		};

		data-pins {
			pins = "gpio13";
			function = "dmic3_data";
			drive-strength = <8>;
			input-enable;
		};
	};
};

&vamacro {
	clocks = <&q6afecc LPASS_CLK_ID_VA_CORE_MCLK LPASS_CLK_ATTRIBUTE_COUPLE_NO>,
		 <&q6afecc LPASS_CLK_ID_VA_CORE_2X_MCLK LPASS_CLK_ATTRIBUTE_COUPLE_NO>,
		 <&q6afecc LPASS_HW_MACRO_VOTE LPASS_CLK_ATTRIBUTE_COUPLE_NO>,
		 <&q6afecc LPASS_HW_DCODEC_VOTE LPASS_CLK_ATTRIBUTE_COUPLE_NO>;
	clock-names = "mclk", "mclk2x", "macro", "dcodec";

	pinctrl-0 = <&dmic1_active &dmic2_active &dmic3_active>;
	pinctrl-names = "default";

	vdd-micb-supply = <&vreg_s4a_1p8>;
	va-vdd-micb-supply = <&vreg_s4a_1p8>;
	qcom,va-vdd-micb-voltage = <1800000>;
	qcom,va-vdd-micb-current = <100000>;
	qcom,dmic-sample-rate = <2400000>;

	status = "okay";
};

&txmacro {
	qcom,va-macro = <&vamacro>;
	vdd-micb-supply = <&vreg_s4a_1p8>;
	qcom,dmic-sample-rate = <2400000>;

	status = "okay";
};

&sound {
	compatible = "qcom,sm8250-sndcard";
	model = "Lenovo Xiaoxin Pad Pro 2021";

	pinctrl-names = "default";
	pinctrl-0 = <&pri_mi2s_active>;

	/* Amp1 keeps the stock "SPK" switch; SPK2-4 start disabled. */
	pin-switches = "SPK2 SPK", "SPK3 SPK", "SPK4 SPK";

	qcom,msm-dmic-en-gpio = <&pm8150b_gpios 12 GPIO_ACTIVE_LOW>;
	/* vendor: <0x08 0x01 0x00> — same PMIC as the DMIC EN, GPIO1 */
	qcom,msm-dmic-sel-gpio = <&pm8150b_gpios 1 GPIO_ACTIVE_HIGH>;

	audio-routing =
		"MM_DL1", "MultiMedia1 Playback",
		"MM_DL2", "MultiMedia2 Playback",
		"MultiMedia3 Capture", "MM_UL3",
		"MultiMedia1 Capture", "MM_UL1",
		"PRI_MI2S_TX", "Capture",
		"Primary MI2S Capture", "Capture",
		"VA DMIC0", "vdd-micb",
		"VA DMIC1", "vdd-micb",
		"VA DMIC2", "vdd-micb",
		"VA DMIC3", "vdd-micb";

	mm1-dai-link {
		link-name = "MultiMedia1";
		cpu {
			sound-dai = <&q6asmdai MSM_FRONTEND_DAI_MULTIMEDIA1>;
		};
	};

	mm2-dai-link {
		link-name = "MultiMedia2";
		cpu {
			sound-dai = <&q6asmdai MSM_FRONTEND_DAI_MULTIMEDIA2>;
		};
	};

	pri-mi2s-dai-link {
		link-name = "Primary MI2S Playback";
		cpu {
			sound-dai = <&q6afedai PRIMARY_MI2S_RX>;
		};

		platform {
			sound-dai = <&q6routing>;
		};

		codec {
			sound-dai = <&spk_amp1 0>, <&spk_amp2 0>,
				    <&spk_amp3 0>, <&spk_amp4 0>;
		};
	};

	mm3-dai-link {
		link-name = "MultiMedia3";
		cpu {
			sound-dai = <&q6asmdai MSM_FRONTEND_DAI_MULTIMEDIA3>;
		};
	};

	tx-dai-link {
		link-name = "TX Capture";
		cpu {
			sound-dai = <&q6afedai TX_CODEC_DMA_TX_3>;
		};

		platform {
			sound-dai = <&q6routing>;
		};

		codec {
			sound-dai = <&txmacro 0>;
		};
	};

	va-dai-link {
		link-name = "VA Capture";
		cpu {
			sound-dai = <&q6afedai VA_CODEC_DMA_TX_0>;
		};

		platform {
			sound-dai = <&q6routing>;
		};

		codec {
			sound-dai = <&vamacro 0>;
		};
	};

	pri-mi2s-cap-dai-link {
		link-name = "Primary MI2S Capture";
		cpu {
			sound-dai = <&q6afedai PRIMARY_MI2S_TX>;
		};

		platform {
			sound-dai = <&q6routing>;
		};

		codec {
			sound-dai = <&es7210>;
		};
	};
};
